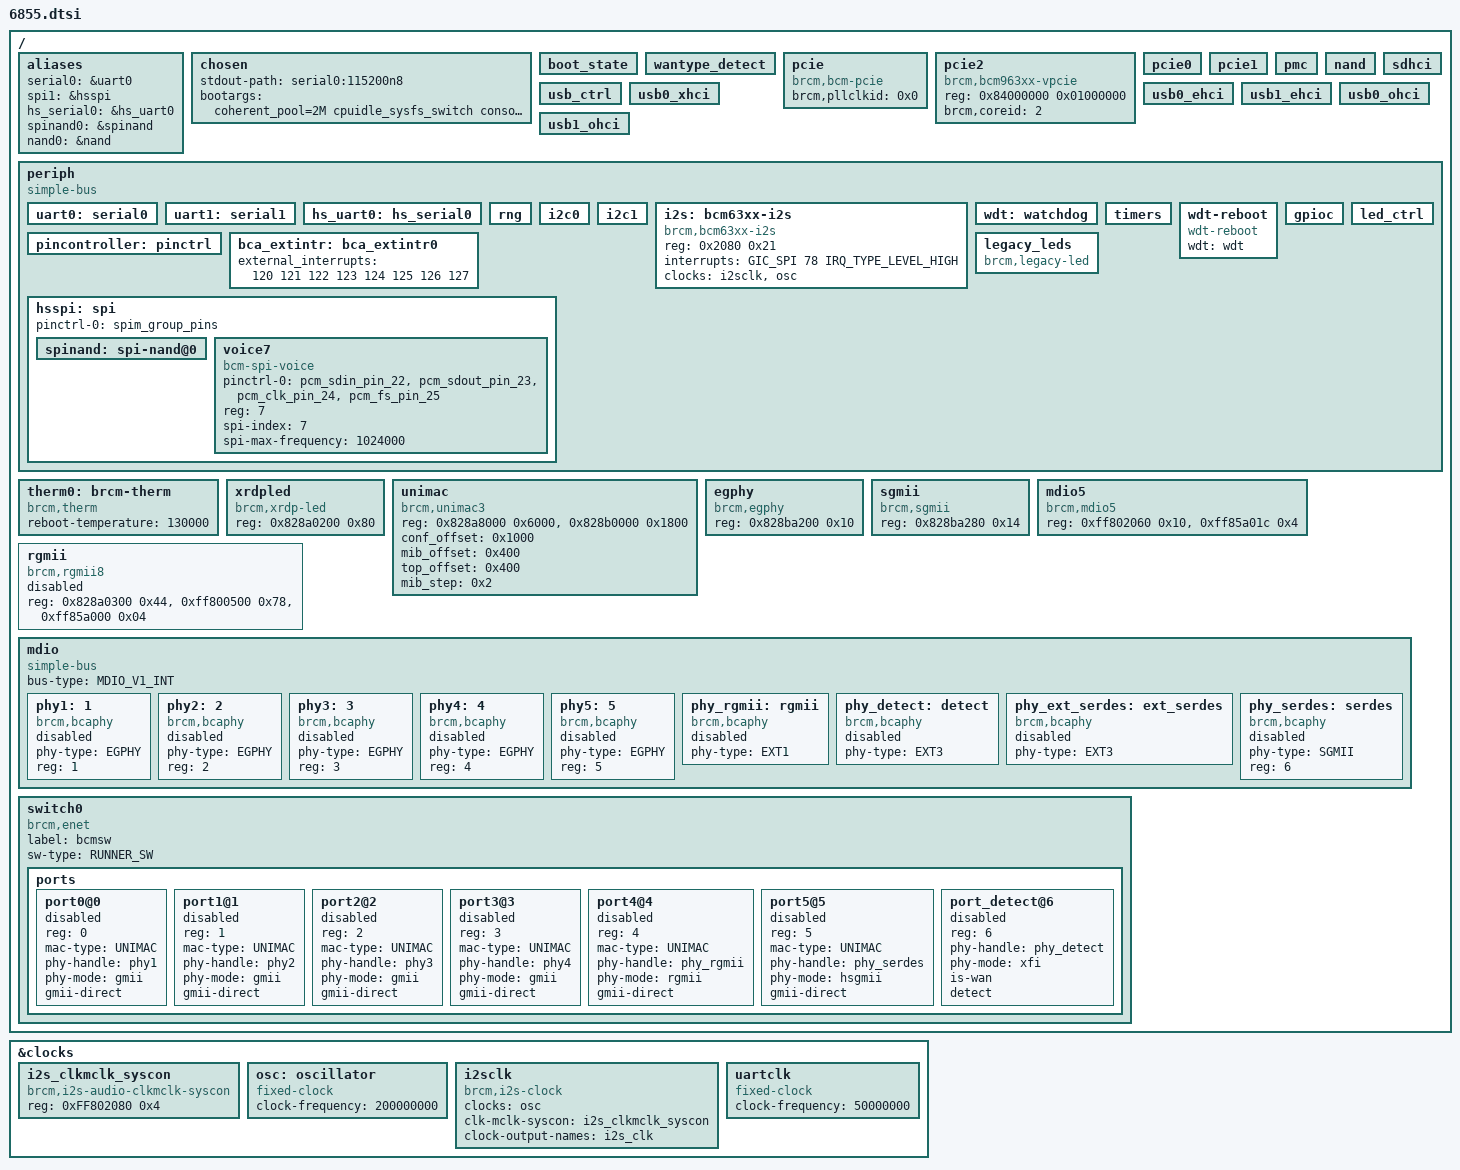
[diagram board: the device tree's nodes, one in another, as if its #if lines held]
/dts-v1/;

#include "linux_autoconf.h"

#include <dt-bindings/interrupt-controller/arm-gic.h>
#include <dt-bindings/interrupt-controller/irq.h>

#include "../../boot_rsvdmem.dtsi"

/ {
	#define MODEL "Broadcom BCM96855"
	#define COMPATIBLE "brcm,bcm96855"

	/* memory reservations */
	#include "../../bcm_rsvdmem.dtsi"		

	aliases {
		serial0		= &uart0;
		spi1		= &hsspi; /* 0 = legacy, 1 = high speed */
		hs_serial0	= &hs_uart0;
		spinand0	= &spinand;
		nand0		= &nand;
	};

	chosen {
		stdout-path = "serial0:115200n8";
		bootargs = "coherent_pool=2M cpuidle_sysfs_switch console=ttyAMA0,115200 earlycon rootwait pci=pcie_bus_safe";
	};

	/* memc */
	#include "../../ip/memc.dtsi"

	/* boot state */
	boot_state: boot_state {
		#define RESET_REASON_OFFSET		0xff802628
		#define RESET_REASON_SIZE		0x4
		#define RESET_STATUS_OFFSET		0xff85a018
		#define RESET_STATUS_SIZE		0x4
		#include "../../ip/bcm_boot_state_v2.dtsi"
	};

	/* wan type auto detect */
	wantype_detect {
		#define GPON_GENERAL_CONFIG_ADDR	0x828B9000
		#define GPON_GENERAL_CONFIG_SIZE	0x10
		#define EPON_TOP_ADDR			0x828B4000
		#define EPON_TOP_SIZE			0x1C
		#define EPON_LIF_ADDR			0x828B5800
		#define EPON_LIF_SIZE			0x110
		#define EPON_XPCSR_ADDR			0x828B7000
		#define EPON_XPCSR_SIZE			0x124
		#define NGPON_RXGEN_ADDR		0x828BC000
		#define NGPON_RXGEN_SIZE		0x80
		#include "../../ip/bcm_wantype_detect.dtsi"
	};

#if defined(CONFIG_BCM_PCIE_HCD) || defined (CONFIG_BCM_PCIE_HCD_MODULE)
    /* pcie common */
	pcie: pcie {
		compatible = "brcm,bcm-pcie";
		device_type = "cpci";
		brcm,pllclkid = <0x0>;
	};

	/* pcie core 2 */
	pcie2: pcie2 {
		compatible = "brcm,bcm963xx-vpcie";
		device_type = "vpci";
		reg = <0x84000000 0x01000000>;
		brcm,coreid = <2>;
	};

	/* pcie core 0 */
	pcie0: pcie0 {
		#define PCIE_ID				0
		#define PCIE_SPI			43
		#define PCIE_ADDR			0x80040000
		#define PCIE_SIZE			0x0000A000
					      /*           flags    pci_addr     cpu_addr     size */
		#define PCIE_RANGE			0x02000000 0 0xC0000000 0xC0000000 0 0x10000000
		#include "../../ip/bcm_pcie_core.dtsi"
	};

	/* pcie core 1 */
	pcie1: pcie1 {
		#define PCIE_ID				1
		#define PCIE_SPI			44
		#define PCIE_ADDR			0x80050000
		#define PCIE_SIZE			0x0000A000
					      /*           flags    pci_addr     cpu_addr     size */
		#define PCIE_RANGE			0x02000000 0 0xD0000000 0xD0000000 0 0x10000000
		#include "../../ip/bcm_pcie_core.dtsi"
	};
#endif // defined(CONFIG_BCM_PCIE_HCD) || defined (CONFIG_BCM_PCIE_HCD_MODULE)

	/* PMC */
	pmc: pmc {
		#define PMC_REG_OFFSET              0xffb20060 
		#define PMC_REG_SIZE                0x1e0
		#include "../../ip/bcm_pmc_lite.dtsi"
	};

	/* NAND controller. Although it is on PERIPH bus, but to facilitate single
		device tree for linux/uboot and because uboot cannot interpret composite
		addresses has no scope */
	nand: nand {
		#define NAND_CTRL_OFFSET		0xff801800
		#define NAND_CTRL_SIZE			0x400
		#define NAND_INTR_OFFSET		0xff802000
		#define NAND_INTR_SIZE			0x10
		#define NAND_CACHE_OFFSET		0xff801C00
		#define NAND_CACHE_SIZE			0x200
		#include "../../ip/bcm_nand7_1.dtsi"
	};

	/* EMMC */
	sdhci: sdhci {
		#define SDHCI_OFFSET			0xff810000
		#define SDHCI_SIZE			0x100
		#define SDHCI_TOPCFG_OFFSET		0xff810100
		#define SDHCI_TOPCFG_SIZE		0x100
		#define SDHCI_BOOT_OFFSET		0xff810200
		#define SDHCI_BOOT_SIZE			0x40
		#define SDHCI_AHBSS_CTRL_OFFSET		0xff810300
		#define SDHCI_AHBSS_CTRL_SIZE		0x100
		#define SDIO_EMMC_SPI			86
		#include "../../ip/bcm_sdhci.dtsi"
	};

    /* usb */
    usb_ctrl: usb_ctrl {
        #define USB_CTRL_ADDR       0x8000c200
        #define USB_CTRL_SIZE       0x100
        #include "../../ip/bcm_usb_ctrl.dtsi"
    };

	usb0_xhci: usb0_xhci {
		#define USB_ADDR            0x8000d000
		#define USB_SIZE            0x1000
		#define USB_IRQ             74
		#include "../../ip/bcm_usb_xhci.dtsi"
	};

    usb0_ehci: usb0_ehci {
        #define USB_ADDR            0x8000c300
        #define USB_SIZE            0x100
        #define USB_IRQ             73
        #define USB_PORT_ID         0
        #include "../../ip/bcm_usb_ehci.dtsi"
    };

    usb1_ehci: usb1_ehci {
        #define USB_ADDR            0x8000c500
        #define USB_SIZE            0x100
        #define USB_IRQ             73
        #define USB_PORT_ID         1
        #include "../../ip/bcm_usb_ehci.dtsi"
    };

    usb0_ohci: usb0_ohci {
        #define USB_ADDR            0x8000c400
        #define USB_SIZE            0x100
        #define USB_IRQ             72
        #define USB_PORT_ID         0
        #include "../../ip/bcm_usb_ohci.dtsi"
    };

    usb1_ohci: usb1_ohci {
        #define USB_ADDR            0x8000c600
        #define USB_SIZE            0x100
        #define USB_IRQ             72
        #define USB_PORT_ID         1
        #include "../../ip/bcm_usb_ohci.dtsi"
    };

	/* clocks */
	#define PERIPH_CLK			200000000
	#define HS_SPI_PLL_CLK		200000000
	#include "../../ip/bcm_clocks.dtsi"

	periph {
		compatible = "simple-bus";
		#address-cells = <1>;
		#size-cells = <1>;
		ranges = <0x0 0xff800000 0x100000>;

		/* UART */
		uart0: serial0 {
			#define UART_OFFSET			0x12000
			#define UART_SIZE			0x1000
			#define UART_SPI			32
			#define UART_CLK_LABEL		refclk50mhz
			#define UART_CLK			50000000
			#include "../../ip/bcm_arm_uart.dtsi"
		};

		uart1: serial1 {
			#define UART_OFFSET			0x13000
			#define UART_SIZE			0x1000
			#define UART_SPI			33
			#define UART_CLK_LABEL		refclk50mhz
			#define UART_CLK			50000000
			#include "../../ip/bcm_arm_uart.dtsi"
		};

		hs_uart0: hs_serial0 {
			#define UART_OFFSET			0xff810400
			#define UART_SIZE			0x1E0
			#define UART_SPI			34
			#include "../../ip/bcm_hs_uart.dtsi"
		};

		rng: rng {
			#define RNG200_OFFSET		0x00000b80
			#define RNG200_SIZE			0x30
			#include "../../ip/bcm_rng200.dtsi"
		};

		/* i2c */
		i2c0: i2c0 {
			#define I2C_OFFSET			0x2100
			#define I2C_SIZE			0x60
			#include "../../ip/bcm_i2c_bus.dtsi"
		};

		i2c1: i2c1 {
			#define I2C_OFFSET			0x5a800
			#define I2C_SIZE			0x60
			#include "../../ip/bcm_i2c_bus.dtsi"
		};

		i2s: bcm63xx-i2s {
			compatible		= "brcm,bcm63xx-i2s";
			reg				= <0x2080 0x21>;
			interrupts		= <GIC_SPI 78 IRQ_TYPE_LEVEL_HIGH>;
			clocks			= <&i2sclk>, <&osc>;
			clock-names		= "i2sclk","i2sosc";
		};

		/* watchdog */
		wdt: watchdog {
			#define WATCHDOG_OFFSET		0x480
			#define WATCHDOG_SIZE		0x14
			#define WATCHDOG_TIMEOUT	80
			#include "../../ip/bcm_wdt.dtsi"
		};

		/* periph timers */
		timers: timers {
			#define TIMERS_OFFSET		0x400
			#define TIMERS__SIZE		0x48
			#define TIMER0_SPI			11
			#define TIMER1_SPI			12
			#define TIMER2_SPI			13
			#define TIMER3_SPI			14
			#include "../../ip/bcm_timer.dtsi"
		};

		/* watchdog reboot */
		wdt-reboot {
			compatible	= "wdt-reboot";
			wdt			= <&wdt>;
		};

		pincontroller: pinctrl {
			#define PINCTRL_OFFSET		0x554
			#define PINCTRL_SIZE		0xc
			#define PINCTRL_NUM_PINS	105
			#define PINCTRL_NUM_FUNC	8
			#define PINCTRL_GPIO_FUNC	4
			#include "../../ip/bcm_bca_pinctrl.dtsi"
			#include "6855_pinctrl.dtsi"
		};

		/* gpio */
		gpioc: gpioc {
			#define GPIO_DIR_OFFSET		0x500
			#define GPIO_DIR_SIZE		0x20
			#define GPIO_DATA_OFFSET	0x520
			#define GPIO_DATA_SIZE		0x20
			#define NUM_OF_GPIOS		105
			#include "../../ip/bcm_bca_gpio.dtsi"
		};

		/* external interrups */
		bca_extintr: bca_extintr0 {
			#define EXTINTR_OFFSET		0x4
			#define EXTINTR_SIZE		0x48
			#define MAX_EXT_INTR		8
			#include "../../ip/bcm_bca_extintr.dtsi"
			external_interrupts = <120 121 122 123 124 125 126 127>;
		};

		/* HS SPI */
		hsspi: spi {
			pinctrl-0 = <&spim_group_pins>;
			pinctrl-names = "default";
			#define HS_SPI_OFFSET		0x1000
			#define HS_SPI_SIZE			0x600
			#define HS_SPI_MAX_FREQ		100000000
			#include "../../ip/bcm_hsspi.dtsi"

			spinand: spi-nand@0 {
				#define SPINAND_MAX_FREQ	50000000
				#include "../../ip/bcm_spinand.dtsi"
			};

			voice7 {
				pinctrl-0 = <&pcm_sdin_pin_22 &pcm_sdout_pin_23 &pcm_clk_pin_24 &pcm_fs_pin_25>;
				pinctrl-names = "default";
				compatible = "bcm-spi-voice";
				reg = <7>; /* chip select 7 */
				spi-index = <7>;/* ZSI/ISI header position index */
				spi-max-frequency = <1024000>;
			};
		};

		/* Led Controller */
		led_ctrl: led_ctrl {
			#define CLED_GLBL_CTRL_OFFSET           0x3000
			#define CLED_GLBL_CTRL_SIZE             0x4
			#define CLED_HW_EN_OFFSET               0x3004
			#define CLED_HW_EN_SIZE                 0x4
			#define CLED_SER_SHIFT_OFFSET           0x3008
			#define CLED_SER_SHIFT_SIZE             0x4
			#define CLED_HW_POLARITY_OFFSET         0x300c
			#define CLED_HW_POLARITY_SIZE           0x4
			#define CLED_SW_SET_OFFSET              0x3010
			#define CLED_SW_SET_SIZE                0x4
			#define CLED_SW_POLARITY_OFFSET         0x3014
			#define CLED_SW_POLARITY_SIZE           0x4
			#define CLED_CH_ACTIVATE_OFFSET         0x301c
			#define CLED_CH_ACTIVATE_SIZE           0x4
			#define CLED_XX_CONFIG_OFFSET           0x3020
			#define CLED_XX_CONFIG_SIZE             0x200
			#define CLED_SW_CLEAR_OFFSET            0x3444
			#define CLED_SW_CLEAR_SIZE              0x4
			#define CLED_SW_STATUS_OFFSET           0x3448
			#define CLED_SW_STATUS_SIZE             0x4
			#define CLED_OUT_MUX_OFFSET             0x3460
			#define CLED_OUT_MUX_SIZE               0x20
			#define CLED_SERIAL_POLARITY_OFFSET     0x3454
			#define CLED_SERIAL_POLARITY_SIZE       0x4
			#define CLED_PARALLEL_POLARITY_OFFSET   0x3018
			#define CLED_PARALLEL_POLARITY_SIZE     0x4
			#define MAX_SUPPORTED_LEDS              32

			status = "okay";
			#include "../../ip/bcm_cled_ctrl.dtsi"
			#include "6855_leds.dtsi"
		};

		legacy_leds: legacy_leds {
			compatible = "brcm,legacy-led";
 		};

	};

    therm0: brcm-therm {
		compatible = "brcm,therm";
		reboot-temperature = <130000>; /* millicelsius */
	};

    xrdpled {
		compatible = "brcm,xrdp-led";
		reg = <0x828a0200 0x80>;
    };

    unimac {
        compatible = "brcm,unimac3";
        reg = <0x828a8000 0x6000>,
              <0x828b0000 0x1800>;
        conf_offset = <0x1000>;
        mib_offset = <0x400>;
        top_offset = <0x400>;
        mib_step = <0x2>;
    };

    egphy: egphy {
		compatible = "brcm,egphy";
        reg = <0x828ba200 0x10>;
    };

    sgmii {
		compatible = "brcm,sgmii";
        reg = <0x828ba280 0x14>;
    };

    mdio5 {
		compatible = "brcm,mdio5";
        reg = <0xff802060 0x10>,
              <0xff85a01c 0x4>;
    };

	rgmii: rgmii {
        compatible = "brcm,rgmii8";
        reg = <0x828a0300 0x44>,
              <0xff800500 0x78>,
              <0xff85a000 0x04>;
        status = "disabled";
	};

	mdio: mdio {
		compatible = "simple-bus";
		bus-type = "MDIO_V1_INT";
		#address-cells = <1>;
		#size-cells = <0>;

		phy1:1 {
			compatible = "brcm,bcaphy";
			phy-type = "EGPHY";
			reg = <1>;
			status = "disabled";
		};

		phy2:2 {
			compatible = "brcm,bcaphy";
			phy-type = "EGPHY";
			reg = <2>;
			status = "disabled";
		};

		phy3:3 {
			compatible = "brcm,bcaphy";
			phy-type = "EGPHY";
			reg = <3>;
			status = "disabled";
		};

		phy4:4 {
			compatible = "brcm,bcaphy";
			phy-type = "EGPHY";
			reg = <4>;
			status = "disabled";
		};

		phy5:5 {
			compatible = "brcm,bcaphy";
			phy-type = "EGPHY";
			reg = <5>;
			status = "disabled";
		};

		phy_rgmii:rgmii {
			compatible = "brcm,bcaphy";
			phy-type = "EXT1";
			status = "disabled";
		};

		phy_detect:detect {
			compatible = "brcm,bcaphy";
			phy-type = "EXT3";
			status = "disabled";
		};

		phy_ext_serdes:ext_serdes {
			compatible = "brcm,bcaphy";
			phy-type = "EXT3";
			status = "disabled";
		};

		phy_serdes:serdes {
			compatible = "brcm,bcaphy";
			phy-type = "SGMII";
			reg = <6>;
			status = "disabled";
		};
	};

	switch0: switch0 {
		compatible = "brcm,enet";
		label = "bcmsw";
		sw-type = "RUNNER_SW";

		ports {
			#address-cells = <1>;
			#size-cells = <0>;

			port0@0 {
				reg = <0>;
				mac-type = "UNIMAC";
				phy-handle = <&phy1>;
				phy-mode = "gmii";
				gmii-direct;
				status = "disabled";
			};

			port1@1 {
				reg = <1>;
				mac-type = "UNIMAC";
				phy-handle = <&phy2>;
				phy-mode = "gmii";
				gmii-direct;
				status = "disabled";
			};

			port2@2 {
				reg = <2>;
				mac-type = "UNIMAC";
				phy-handle = <&phy3>;
				phy-mode = "gmii";
				gmii-direct;
				status = "disabled";
			};

			port3@3 {
				reg = <3>;
				mac-type = "UNIMAC";
				phy-handle = <&phy4>;
				phy-mode = "gmii";
				gmii-direct;
				status = "disabled";
			};

			port4@4 {
				reg = <4>;
				mac-type = "UNIMAC";
				phy-handle = <&phy_rgmii>;
				phy-mode = "rgmii";
				gmii-direct;
				status = "disabled";
			};

			port5@5 {
				reg = <5>;
				mac-type = "UNIMAC";
				phy-handle = <&phy_serdes>;
				phy-mode = "hsgmii";
				gmii-direct;
				status = "disabled";
			};

			port_detect@6 {
				reg = <6>;
				phy-handle = <&phy_detect>;
				phy-mode = "xfi";
				is-wan;
				detect;
				status = "disabled";
			};
		};
	};
};

&clocks {
	#address-cells = <1>;
	#size-cells    = <1>;
	ranges;

	i2s_clkmclk_syscon: i2s_clkmclk_syscon{
		compatible			= "brcm,i2s-audio-clkmclk-syscon", "syscon";
		reg					= <0xFF802080 0x4>;
	};
	osc: oscillator {
		#clock-cells		= <0>;
		compatible			= "fixed-clock";
		clock-frequency		= <200000000>;
	};

	i2sclk: i2sclk {
		#clock-cells		= <0>;
		compatible			= "brcm,i2s-clock";
		clocks				= <&osc>;
		clk-mclk-syscon		= <&i2s_clkmclk_syscon>;
		clock-output-names	= "i2s_clk";
	};
 
	uartclk: uartclk {
		compatible			= "fixed-clock";
		#clock-cells		= <0>;
		clock-frequency		= <50000000>;
	};
};
